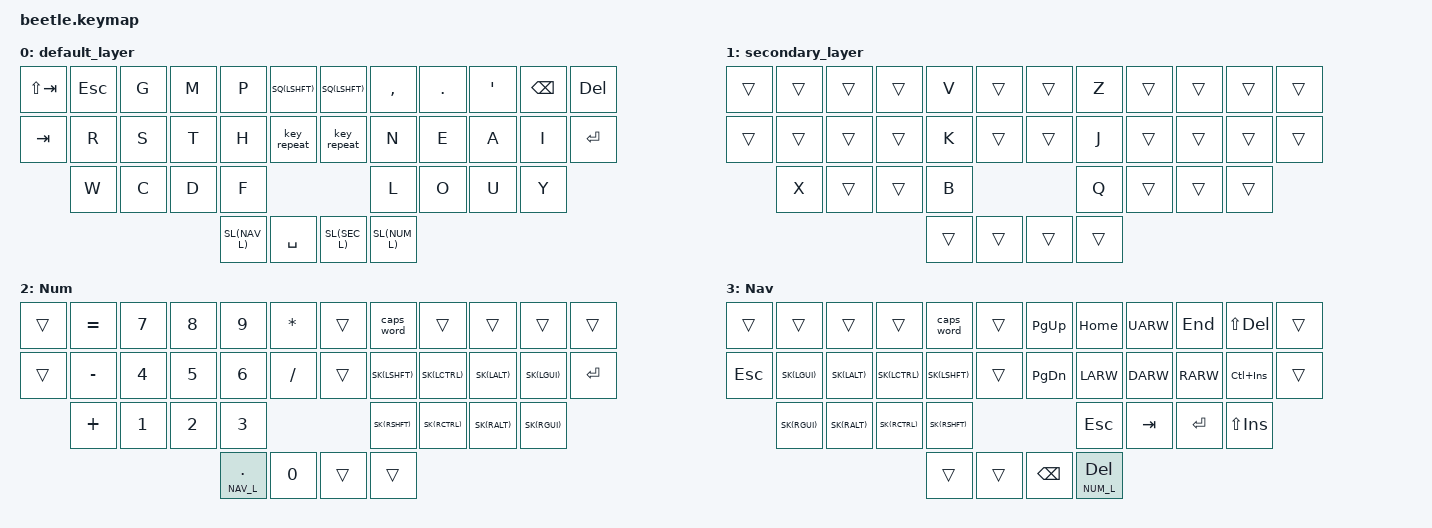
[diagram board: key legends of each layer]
/*
 * Copyright (c) 2020 The ZMK Contributors
 * SPDX-License-Identifier: MIT
 *
 * This is a APT24 keymap for the Beetle keyboard.
 * Last edited by James White, December 22, 2021.
 */

#include <behaviors.dtsi>
#include <dt-bindings/zmk/keys.h>
#include <dt-bindings/zmk/bt.h>

&kscan0 {
    debounce-period = <10>;
};

#define DEF_L 0
#define SEC_L 1
#define NUM_L 2
#define NAV_L 3

&sl {
    release-after-ms = <5000>;
    quick-release;
};
&sk {
    release-after-ms = <10000>;
};
&caps_word {
  continue-list = <UNDERSCORE MINUS BACKSPACE>;
};

/ {
    behaviors {
        sq: sticky_key_quick_release {
            compatible = "zmk,behavior-sticky-key";
            label = "sticky key quick release";
            #binding-cells = <1>;
            bindings = <&kp>;
            release-after-ms = <10000>;
            quick-release;
        };
        nl: not_so_sticky_layer {
            compatible = "zmk,behavior-hold-tap";
            label = "not so sticky layer";
            #binding-cells = <2>;
            tapping_term_ms = <200>;
            flavor = "tap-preferred";
            bindings = <&mo>, <&sl>;
        };
        nk: not_so_sticky_key {
            compatible = "zmk,behavior-hold-tap";
            label = "not so sticky key";
            #binding-cells = <2>;
            tapping_term_ms = <200>;
            flavor = "tap-preferred";
            bindings = <&kp>, <&sk>;
        };
        nq: not_so_sticky_quick_release {
            compatible = "zmk,behavior-hold-tap";
            label = "not so sticky quick release";
            #binding-cells = <2>;
            tapping_term_ms = <200>;
            flavor = "tap-preferred";
            bindings = <&kp>, <&sq>;
        };
        f113: f_one_thirteen {
            compatible = "zmk,behavior-mod-morph";
            label = "F1 F13";
            #binding-cells = <0>;
            bindings = <&kp F1>, <&kp F13>;
            mods = <(MOD_RALT)>;
        };
        f214: f_two_fourteen {
            compatible = "zmk,behavior-mod-morph";
            label = "F2 F14";
            #binding-cells = <0>;
            bindings = <&kp F2>, <&kp F14>;
            mods = <(MOD_RALT)>;
        };
        f315: f_three_fifteen {
            compatible = "zmk,behavior-mod-morph";
            label = "F3 F15";
            #binding-cells = <0>;
            bindings = <&kp F3>, <&kp F15>;
            mods = <(MOD_RALT)>;
        };
        f416: f_four_sixteen {
            compatible = "zmk,behavior-mod-morph";
            label = "F4 F15";
            #binding-cells = <0>;
            bindings = <&kp F4>, <&kp F15>;
            mods = <(MOD_RALT)>;
        };
        f517: f_five_seventeen {
            compatible = "zmk,behavior-mod-morph";
            label = "F5 F17";
            #binding-cells = <0>;
            bindings = <&kp F5>, <&kp F17>;
            mods = <(MOD_RALT)>;
        };
        f618: f_six_eighteen {
            compatible = "zmk,behavior-mod-morph";
            label = "F6 F18";
            #binding-cells = <0>;
            bindings = <&kp F6>, <&kp F18>;
            mods = <(MOD_RALT)>;
        };
        f719: f_seven_nineteen {
            compatible = "zmk,behavior-mod-morph";
            label = "F7 F19";
            #binding-cells = <0>;
            bindings = <&kp F7>, <&kp F19>;
            mods = <(MOD_RALT)>;
        };
        f820: f_eight_twenty {
            compatible = "zmk,behavior-mod-morph";
            label = "F8 F20";
            #binding-cells = <0>;
            bindings = <&kp F8>, <&kp F20>;
            mods = <(MOD_RALT)>;
        };
        f921: f_nine_twentyone {
            compatible = "zmk,behavior-mod-morph";
            label = "F9 F21";
            #binding-cells = <0>;
            bindings = <&kp F9>, <&kp F21>;
            mods = <(MOD_RALT)>;
        };
        f1022: f_ten_twentytwo {
            compatible = "zmk,behavior-mod-morph";
            label = "F10 F22";
            #binding-cells = <0>;
            bindings = <&kp F10>, <&kp F22>;
            mods = <(MOD_RALT)>;
        };
        f1123: f_eleven_twentythree {
            compatible = "zmk,behavior-mod-morph";
            label = "F11 F23";
            #binding-cells = <0>;
            bindings = <&kp F11>, <&kp F23>;
            mods = <(MOD_RALT)>;
        };
        f1224: f_twelve_twentyfour {
            compatible = "zmk,behavior-mod-morph";
            label = "F12 F24";
            #binding-cells = <0>;
            bindings = <&kp F12>, <&kp F24>;
            mods = <(MOD_RALT)>;
        };
    };
    combos {
        compatible = "zmk,combos";
        combo_left_brace {
            timeout-ms = <25>;
            key-positions = <2 3>;
            layers = <0>;
            bindings = <&kp LBRC>;
        };
        combo_right_brace {
            timeout-ms = <25>;
            key-positions = <3 4>;
            layers = <0>;
            bindings = <&kp RBRC>;
        };
        combo_left_parenthesis {
            timeout-ms = <25>;
            key-positions = <14 15>;
            layers = <0>;
            bindings = <&kp LPAR>;
        };
        combo_right_parenthesis {
            timeout-ms = <25>;
            key-positions = <15 16>;
            layers = <0>;
            bindings = <&kp RPAR>;
        };
        combo_left_bracket {
            timeout-ms = <25>;
            key-positions = <25 26>;
            layers = <0>;
            bindings = <&kp LBKT>;
        };
        combo_right_bracket {
            timeout-ms = <25>;
            key-positions = <26 27>;
            layers = <0>;
            bindings = <&kp RBKT>;
        };
        combo_grave {
            timeout-ms = <25>;
            key-positions = <7 8>;
            layers = <0>;
            bindings = <&kp GRAVE>;
        };
        combo_backslash {
            timeout-ms = <25>;
            key-positions = <8 9>;
            layers = <0>;
            bindings = <&kp BSLH>;
        };
        combo_minus {
            timeout-ms = <25>;
            key-positions = <19 20>;
            layers = <0>;
            bindings = <&kp MINUS>;
        };
        combo_equal {
            timeout-ms = <25>;
            key-positions = <20 21>;
            layers = <0>;
            bindings = <&kp EQUAL>;
        };
        combo_semicolon {
            timeout-ms = <25>;
            key-positions = <28 29>;
            layers = <0>;
            bindings = <&kp SEMI>;
        };
        combo_forward_slash {
            timeout-ms = <25>;
            key-positions = <29 30>;
            layers = <0>;
            bindings = <&kp SLASH>;
        };
        combo_f_one {
            timeout-ms = <25>;
            key-positions = <0 12>;
            layers = <2 3>;
            bindings = <&f113>;
        };
        combo_f_two {
            timeout-ms = <25>;
            key-positions = <1 13>;
            layers = <2 3>;
            bindings = <&f214>;
        };
        combo_f_three {
            timeout-ms = <25>;
            key-positions = <2 14>;
            layers = <2 3>;
            bindings = <&f315>;
        };
        combo_f_four {
            timeout-ms = <25>;
            key-positions = <3 15>;
            layers = <2 3>;
            bindings = <&f416>;
        };
        combo_f_five {
            timeout-ms = <25>;
            key-positions = <4 16>;
            layers = <2 3>;
            bindings = <&f517>;
        };
        combo_f_six {
            timeout-ms = <25>;
            key-positions = <5 17>;
            layers = <2 3>;
            bindings = <&f618>;
        };
        combo_f_seven {
            timeout-ms = <25>;
            key-positions = <6 18>;
            layers = <2 3>;
            bindings = <&f719>;
        };
        combo_f_eight {
            timeout-ms = <25>;
            key-positions = <7 19>;
            layers = <2 3>;
            bindings = <&f820>;
        };
        combo_f_nine {
            timeout-ms = <25>;
            key-positions = <8 20>;
            layers = <2 3>;
            bindings = <&f921>;
        };
        combo_f_ten {
            timeout-ms = <25>;
            key-positions = <9 21>;
            layers = <2 3>;
            bindings = <&f1022>;
        };
        combo_f_eleven {
            timeout-ms = <25>;
            key-positions = <10 22>;
            layers = <2 3>;
            bindings = <&f1123>;
        };
        combo_f_twelve {
            timeout-ms = <25>;
            key-positions = <11 23>;
            layers = <2 3>;
            bindings = <&f1224>;
        };
        combo_mute {
            timeout-ms = <25>;
            key-positions = <14 25>;
            layers = <2 3>;
            bindings = <&kp C_MUTE>;
        };
        combo_vol_down {
            timeout-ms = <25>;
            key-positions = <15 26>;
            layers = <2 3>;
            bindings = <&kp C_VOLUME_DOWN>;
        };
        combo_vol_up {
            timeout-ms = <25>;
            key-positions = <16 27>;
            layers = <2 3>;
            bindings = <&kp C_VOLUME_UP>;
        };
        combo_media_play_pause {
            timeout-ms = <25>;
            key-positions = <19 28>;
            layers = <2 3>;
            bindings = <&kp C_PLAY_PAUSE>;
        };
        combo_media_prev {
            timeout-ms = <25>;
            key-positions = <20 29>;
            layers = <2 3>;
            bindings = <&kp C_PREV>;
        };
        combo_media_next {
            timeout-ms = <25>;
            key-positions = <16 30>;
            layers = <2 3>;
            bindings = <&kp C_NEXT>;
        };
        combo_ctl_sft_tab {
            timeout-ms = <25>;
            key-positions = <2 3 4>;
            layers = <0>;
            bindings = <&kp LC(LS(TAB))>;
        };
        combo_alt_sft_tab {
            timeout-ms = <25>;
            key-positions = <14 15 16>;
            layers = <0>;
            bindings = <&kp LA(LS(TAB))>;
        };
        combo_gui_sft_tab {
            timeout-ms = <25>;
            key-positions = <25 26 27>;
            layers = <0>;
            bindings = <&kp LG(LS(TAB))>;
        };
        combo_ctl_tab {
            timeout-ms = <25>;
            key-positions = <7 8 9>;
            layers = <0>;
            bindings = <&kp LC(TAB)>;
        };
        combo_alt_tab {
            timeout-ms = <25>;
            key-positions = <19 20 21>;
            layers = <0>;
            bindings = <&kp LA(TAB)>;
        };
        combo_gui_tab {
            timeout-ms = <25>;
            key-positions = <28 29 30>;
            layers = <0>;
            bindings = <&kp LG(TAB)>;
        };
        combo_toggle_number_layer {
            timeout-ms = <25>;
            key-positions = <13 14 15 16>;
            layers = <0 2>;
            bindings = <&tog NUM_L>;
        };
        combo_toggle_navigation_layer {
            timeout-ms = <25>;
            key-positions = <19 20 21 22>;
            layers = <0 3>;
            bindings = <&tog NAV_L>;
        };
        combo_cancel_stickies_left {
            timeout-ms = <25>;
            key-positions = <13 14 15 16>;
            layers = <3>;
            bindings = <&kp F21>;
        };
        combo_cancel_stickies_right {
            timeout-ms = <25>;
            key-positions = <19 20 21 22>;
            layers = <2>;
            bindings = <&kp F21>;
        };
        combo_shift_tab {
            timeout-ms = <25>;
            key-positions = <0 12>;
            bindings = <&kp LS(TAB)>;
        };
        combo_delete {
            timeout-ms = <25>;
            key-positions = <11 23>;
            bindings = <&kp DEL>;
        };
        combo_printscreen {
            timeout-ms = <25>;
            key-positions = <33 34>;
            bindings = <&kp PSCRN>;
        };
    };
};
#define SL(KEY) &nl KEY KEY
#define SK(KEY) &nk KEY KEY
#define SQ(KEY) &nq KEY KEY
#define CAPSWORD &caps_word
#define REPEAT &key_repeat

/ {
    keymap {
        compatible = "zmk,keymap";

        default_layer {
            bindings = <
              &kp LS(TAB) &kp ESC   &kp G     &kp M     &kp P     SQ(LSHFT)       SQ(LSHFT) &kp COMMA &kp DOT   &kp APOS  &kp BSPC  &kp DEL
                &kp TAB   &kp R     &kp S     &kp T     &kp H     REPEAT          REPEAT    &kp N     &kp E     &kp A     &kp I     &kp RET
                          &kp W     &kp C     &kp D     &kp F                               &kp L     &kp O     &kp U     &kp Y
                                                        SL(NAV_L) &kp SPACE       SL(SEC_L) SL(NUM_L)
            >;
        };

        secondary_layer {
            bindings = <
                &trans    &trans    &trans    &trans    &kp V     &trans          &trans    &kp Z     &trans    &trans    &trans    &trans
                &trans    &trans    &trans    &trans    &kp K     &trans          &trans    &kp J     &trans    &trans    &trans    &trans
                          &kp X     &trans    &trans    &kp B                               &kp Q     &trans    &trans    &trans
                                                        &trans    &trans          &trans    &trans
            >;
        };

        num_layer {
            label = "Num";
            bindings = <
                &trans    &kp EQUAL &kp N7    &kp N8    &kp N9    &kp ASTRK       &trans    CAPSWORD  &trans    &trans    &trans    &trans
                &trans    &kp MINUS &kp N4    &kp N5    &kp N6    &kp SLASH       &trans    SK(LSHFT) SK(LCTRL) SK(LALT)  SK(LGUI)  &kp RET
                          &kp PLUS  &kp N1    &kp N2    &kp N3                              SK(RSHFT) SK(RCTRL) SK(RALT)  SK(RGUI)
                                                    &lt NAV_L DOT &kp N0          &trans    &trans
            >;
        };

        nav_layer {
            label = "Nav";
            bindings = <
                &trans    &trans    &trans    &trans    CAPSWORD  &trans          &kp PG_UP &kp HOME  &kp UARW  &kp END   &kp LS(DEL) &trans
                &kp ESC   SK(LGUI)  SK(LALT)  SK(LCTRL) SK(LSHFT) &trans          &kp PG_DN &kp LARW  &kp DARW  &kp RARW  &kp LC(INS) &trans
                          SK(RGUI)  SK(RALT)  SK(RCTRL) SK(RSHFT)                           &kp ESC   &kp TAB   &kp RET   &kp LS(INS)
                                                        &trans    &trans          &kp BSPC  &lt NUM_L DEL
            >;
        };

    };
};
